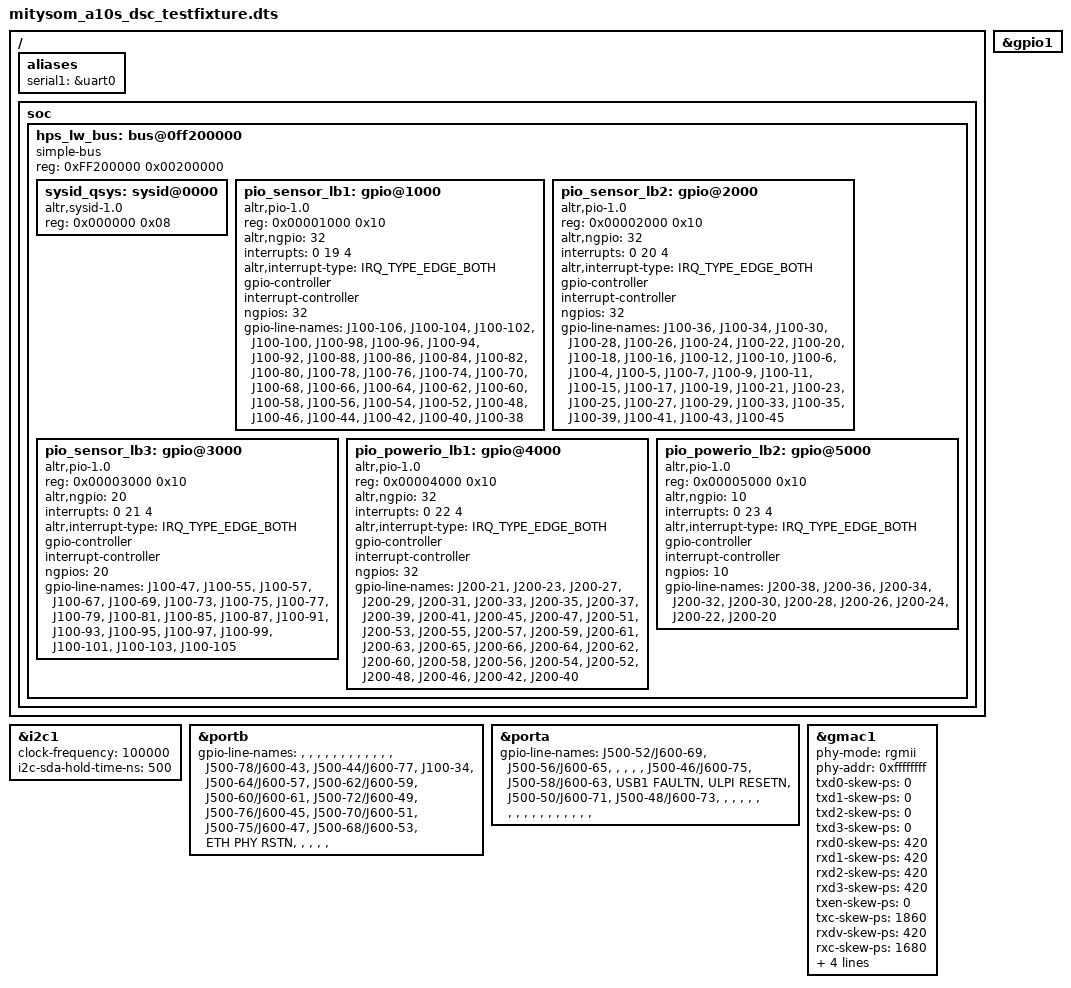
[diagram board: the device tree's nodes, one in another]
/*
 * Copyright (C) 2014-2015 Altera Corporation <www.altera.com>
 *
 * This program is free software; you can redistribute it and/or modify
 * it under the terms of the GNU General Public License as published by
 * the Free Software Foundation; either version 2 of the License, or
 * (at your option) any later version.
 *
 * This program is distributed in the hope that it will be useful,
 * but WITHOUT ANY WARRANTY; without even the implied warranty of
 * MERCHANTABILITY or FITNESS FOR A PARTICULAR PURPOSE.  See the
 * GNU General Public License for more details.
 *
 * You should have received a copy of the GNU General Public License
 * along with this program.  If not, see <http://www.gnu.org/licenses/>.
 */

/dts-v1/;
#include "mitysom_a10s_dsc.dtsi"

/ {
	aliases {
		serial1 = &uart0;
	};

	soc {
		hps_lw_bus: bus@0ff200000 {
			compatible = "simple-bus";
			reg = <0xFF200000 0x00200000>;
			#address-cells = <1>;
			#size-cells = <1>;
			ranges = <0x0 0xFF200000 0x00200000>;
			status = "okay";

			sysid_qsys: sysid@0000 {
				compatible = "altr,sysid-1.0";
				reg = <0x000000 0x08>;
			};

			pio_sensor_lb1: gpio@1000 {
				compatible = "altr,pio-1.0";
				reg = <0x00001000 0x10>;
				altr,ngpio = <32>;
				interrupts = <0 19 4>;
				altr,interrupt-type = <IRQ_TYPE_EDGE_BOTH>;
				#gpio-cells = <2>;
				gpio-controller;
				#interrupt-cells = <1>;
				interrupt-controller;
				ngpios = <32>;
				gpio-line-names =
					"J100-106", /* 0 */
					"J100-104", /* 1 */
					"J100-102", /* 2 */
					"J100-100", /* 3 */
					"J100-98", /* 4 */
					"J100-96", /* 5 */
					"J100-94", /* 6 */
					"J100-92", /* 7 */
					"J100-88", /* 8 */
					"J100-86", /* 9 */
					"J100-84", /* 10 */
					"J100-82", /* 11 */
					"J100-80", /* 12 */
					"J100-78", /* 13 */
					"J100-76", /* 14 */
					"J100-74", /* 15 */
					"J100-70", /* 16 */
					"J100-68", /* 17 */
					"J100-66", /* 18 */
					"J100-64", /* 19 */
					"J100-62", /* 20 */
					"J100-60", /* 21 */
					"J100-58", /* 22 */
					"J100-56", /* 23 */
					"J100-54", /* 24 */
					"J100-52", /* 25 */
					"J100-48", /* 26 */
					"J100-46", /* 27 */
					"J100-44", /* 28 */
					"J100-42", /* 29 */
					"J100-40", /* 30 */
					"J100-38"; /* 31 */
			};

			pio_sensor_lb2: gpio@2000 {
				compatible = "altr,pio-1.0";
				reg = <0x00002000 0x10>;
				altr,ngpio = <32>;
				interrupts = <0 20 4>;
				altr,interrupt-type = <IRQ_TYPE_EDGE_BOTH>;
				#gpio-cells = <2>;
				gpio-controller;
				#interrupt-cells = <1>;
				interrupt-controller;
				ngpios = <32>;
				gpio-line-names =
					"J100-36", /* 32 */
					"J100-34", /* 33 */
					"J100-30", /* 34 */
					"J100-28", /* 35 */
					"J100-26", /* 36 */
					"J100-24", /* 37 */
					"J100-22", /* 38 */
					"J100-20", /* 39 */
					"J100-18", /* 40 */
					"J100-16", /* 41 */
					"J100-12", /* 42 */
					"J100-10", /* 43 */
					"J100-6", /* 44 */
					"J100-4", /* 45 */
					"J100-5", /* 46 */
					"J100-7", /* 47 */
					"J100-9", /* 48 */
					"J100-11", /* 49 */
					"J100-15", /* 50 */
					"J100-17", /* 51 */
					"J100-19", /* 52 */
					"J100-21", /* 53 */
					"J100-23", /* 54 */
					"J100-25", /* 55 */
					"J100-27", /* 56 */
					"J100-29", /* 57 */
					"J100-33", /* 58 */
					"J100-35", /* 59 */
					"J100-39", /* 60 */
					"J100-41", /* 61 */
					"J100-43", /* 62 */
					"J100-45"; /* 63 */
			};

			pio_sensor_lb3: gpio@3000 {
				compatible = "altr,pio-1.0";
				reg = <0x00003000 0x10>;
				altr,ngpio = <20>;
				interrupts = <0 21 4>;
				altr,interrupt-type = <IRQ_TYPE_EDGE_BOTH>;
				#gpio-cells = <2>;
				gpio-controller;
				#interrupt-cells = <1>;
				interrupt-controller;
				ngpios = <20>;
				gpio-line-names =
					"J100-47", /* 64 */
					"J100-55", /* 66 */
					"J100-57", /* 67 */
					"J100-67", /* 68 */
					"J100-69", /* 69 */
					"J100-73", /* 70 */
					"J100-75", /* 71 */
					"J100-77", /* 72 */
					"J100-79", /* 73 */
					"J100-81", /* 74 */
					"J100-85", /* 75 */
					"J100-87", /* 76 */
					"J100-91", /* 77 */
					"J100-93", /* 78 */
					"J100-95", /* 79 */
					"J100-97", /* 80 */
					"J100-99", /* 81 */
					"J100-101", /* 82 */
					"J100-103", /* 83 */
					"J100-105"; /* 84 */
			};

			pio_powerio_lb1: gpio@4000 {
				compatible = "altr,pio-1.0";
				reg = <0x00004000 0x10>;
				altr,ngpio = <32>;
				interrupts = <0 22 4>;
				altr,interrupt-type = <IRQ_TYPE_EDGE_BOTH>;
				#gpio-cells = <2>;
				gpio-controller;
				#interrupt-cells = <1>;
				interrupt-controller;
				ngpios = <32>;
				gpio-line-names =
					"J200-21", /* 0 */
					"J200-23", /* 1 */
					"J200-27", /* 2 */
					"J200-29", /* 3 */
					"J200-31", /* 4 */
					"J200-33", /* 5 */
					"J200-35", /* 6 */
					"J200-37", /* 7 */
					"J200-39", /* 8 */
					"J200-41", /* 9 */
					"J200-45", /* 10 */
					"J200-47", /* 11 */
					"J200-51", /* 12 */
					"J200-53", /* 13 */
					"J200-55", /* 14 */
					"J200-57", /* 15 */
					"J200-59", /* 16 */
					"J200-61", /* 17 */
					"J200-63", /* 18 */
					"J200-65", /* 19 */
					"J200-66", /* 20 */
					"J200-64", /* 21 */
					"J200-62", /* 22 */
					"J200-60", /* 23 */
					"J200-58", /* 24 */
					"J200-56", /* 25 */
					"J200-54", /* 26 */
					"J200-52", /* 27 */
					"J200-48", /* 28 */
					"J200-46", /* 29 */
					"J200-42", /* 30 */
					"J200-40"; /* 31 */
			};


			pio_powerio_lb2: gpio@5000 {
				compatible = "altr,pio-1.0";
				reg = <0x00005000 0x10>;
				altr,ngpio = <10>;
				interrupts = <0 23 4>;
				altr,interrupt-type = <IRQ_TYPE_EDGE_BOTH>;
				#gpio-cells = <2>;
				gpio-controller;
				#interrupt-cells = <1>;
				interrupt-controller;
				ngpios = <10>;
				gpio-line-names =
					"J200-38", /* 32 */
					"J200-36", /* 33 */
					"J200-34", /* 34 */
					"J200-32", /* 35 */
					"J200-30", /* 36 */
					"J200-28", /* 37 */
					"J200-26", /* 38 */
					"J200-24", /* 39 */
					"J200-22", /* 40 */
					"J200-20"; /* 41 */
			};

		};

	};
};

/* sensor board and power board I2C bus */
&i2c1 {
	status = "okay";
	clock-frequency = <100000>;
        i2c-sda-hold-time-ns = <500>;

};

/* gpio needed for EMAC PHY reset */
&gpio1 {
	status = "okay";
};

&portb {
	gpio-line-names =
		"", /* 0 */
		"", /* 1 */
		"", /* 2 */
		"", /* 3 */
		"", /* 4 */
		"", /* 5 */
		"", /* 6 */
		"", /* 7 */
		"", /* 8 */
		"", /* 9 */
		"", /* 10 */
		"", /* 11 */
		"J500-78/J600-43", /* 12 */
		"J500-44/J600-77", /* 13 */
		"J100-34", /* 14 */
		"J500-64/J600-57", /* 15 */
		"J500-62/J600-59", /* 16 */
		"J500-60/J600-61", /* 17 */
		"J500-72/J600-49", /* 18 */
		"J500-76/J600-45", /* 19 */
		"J500-70/J600-51", /* 20 */
		"J500-75/J600-47", /* 21 */
		"J500-68/J600-53", /* 22 */
		"ETH PHY RSTN", /* 23 */
		"", /* 24 */
		"", /* 25 */
		"", /* 26 */
		"", /* 27 */
		""; /* 28 */
};

&porta {
	gpio-line-names =
		"J500-52/J600-69", /* 0 */
		"J500-56/J600-65", /* 1 */
		"", /* 2 */
		"", /* 3 */
		"", /* 4 */
		"", /* 5 */
		"J500-46/J600-75", /* 6 */
		"J500-58/J600-63", /* 7 */
		"USB1 FAULTN", /* 8 */
		"ULPI RESETN", /* 9 */
		"J500-50/J600-71", /* 10 */
		"J500-48/J600-73", /* 11 */
		"", /* 12 */
		"", /* 13 */
		"", /* 14 */
		"", /* 15 */
		"", /* 16 */
		"", /* 17 */
		"", /* 18 */
		"", /* 19 */
		"", /* 20 */
		"", /* 21 */
		"", /* 22 */
		"", /* 23 */
		"", /* 24 */
		"", /* 25 */
		"", /* 26 */
		"", /* 27 */
		""; /* 28 */
};

&gmac1 {
	phy-mode = "rgmii";
	phy-addr = <0xffffffff>; /* probe for phy addr */

	/*
	 * These skews assume the user's FPGA design is adding 600ps of delay
	 * for TX_CLK on Arria 10.
	 *
	 * All skews are offset since hardware skew values for the ksz9031
	 * range from a negative skew to a positive skew.
	 * See the micrel-ksz90x1.txt Documentation file for details.
	 */
	txd0-skew-ps = <0>; /* -420ps */
	txd1-skew-ps = <0>; /* -420ps */
	txd2-skew-ps = <0>; /* -420ps */
	txd3-skew-ps = <0>; /* -420ps */
	rxd0-skew-ps = <420>; /* 0ps */
	rxd1-skew-ps = <420>; /* 0ps */
	rxd2-skew-ps = <420>; /* 0ps */
	rxd3-skew-ps = <420>; /* 0ps */
	txen-skew-ps = <0>; /* -420ps */
	txc-skew-ps = <1860>; /* 960ps */
	rxdv-skew-ps = <420>; /* 0ps */
	rxc-skew-ps = <1680>; /* 780ps */
	max-frame-size = <3800>;
	snps,reset-gpio = <&portb 23 GPIO_ACTIVE_LOW>;
	snps,reset-delays-us = <0 10000 1000000>;
	snps,reset-active-low;
	status = "okay";
};

